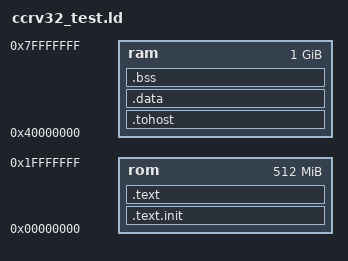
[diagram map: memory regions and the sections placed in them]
/*======================================================================*/
/* Linker script to perform ccrv32 tests                                */
/*======================================================================*/

/*----------------------------------------------------------------------*/
/* Setup                                                                */
/*----------------------------------------------------------------------*/

OUTPUT_ARCH( "riscv" )
MEMORY
{
 rom : ORIGIN = 0x00000000, LENGTH = 0x20000000
 ram : ORIGIN = 0x40000000, LENGTH = 0x40000000
}

/*----------------------------------------------------------------------*/
/* Sections                                                             */
/*----------------------------------------------------------------------*/

ENTRY(_start)

SECTIONS
{

  .text.init : {
    . = 0x100;
    *(.text.init)
  } > rom

  .text : {
    *(.text)
    . = ALIGN(4);
    _data_load = .;
  } > rom

  .tohost : { *(.tohost) } > ram

  .data : AT (_data_load) {
    . = ALIGN(4);
    _sdata = .;
    *(.data)
    _edata = .;
  } > ram

  .bss : { *(.bss) } > ram

  _end = .;

}

